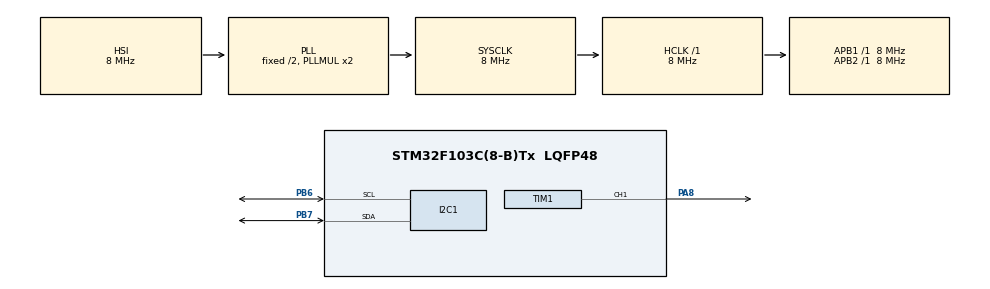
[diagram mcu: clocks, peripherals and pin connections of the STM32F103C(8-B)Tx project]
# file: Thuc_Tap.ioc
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Mcu.Family=STM32F1
Mcu.Name=STM32F103C(8-B)Tx
Mcu.Package=LQFP48
NVIC.I2C1_EV_IRQn=true\:0\:0\:false\:false\:true\:true\:true\:true
NVIC.PriorityGroup=NVIC_PRIORITYGROUP_4
PA13.Mode=Serial_Wire
PA13.Signal=SYS_JTMS-SWDIO
PA14.Mode=Serial_Wire
PA14.Signal=SYS_JTCK-SWCLK
PA8.Signal=S_TIM1_CH1
PB6.Mode=I2C
PB6.Signal=I2C1_SCL
PB7.Mode=I2C
PB7.Signal=I2C1_SDA
ProjectManager.HeapSize=0x200
ProjectManager.StackSize=0x400
ProjectManager.TargetToolchain=MDK-ARM V5.32
RCC.AHBFreq_Value=8000000
RCC.APB1Freq_Value=8000000
RCC.APB1TimFreq_Value=8000000
RCC.APB2Freq_Value=8000000
RCC.APB2TimFreq_Value=8000000
RCC.HCLKFreq_Value=8000000
RCC.SYSCLKFreq_VALUE=8000000
RCC.SYSCLKSource=RCC_SYSCLKSOURCE_PLLCLK
RCC.USBFreq_Value=8000000
SH.S_TIM1_CH1.0=TIM1_CH1,PWM Generation1 CH1
TIM1.Channel-PWM\ Generation1\ CH1=TIM_CHANNEL_1
TIM1.Period=999
TIM1.Prescaler=159
TIM1.Pulse-PWM\ Generation1\ CH1=100
VP_TIM1_VS_ClockSourceINT.Mode=Internal
board=custom

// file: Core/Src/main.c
/* USER CODE BEGIN Header */
/**
  ******************************************************************************
  * @file           : main.c
  * @brief          : Main program body
  ******************************************************************************
  * @attention
  *
  * Copyright (c) 2022 STMicroelectronics.
  * All rights reserved.
  *
  * This software is licensed under terms that can be found in the LICENSE file
  * in the root directory of this software component.
  * If no LICENSE file comes with this software, it is provided AS-IS.
  *
  ******************************************************************************
  */
/* USER CODE END Header */
#include "main.h"

/* USER CODE BEGIN Includes */
#include "DS3231.h"
#include "SG90.h"
/* USER CODE END Includes */

/* USER CODE BEGIN PTD */
DS3231_Name DS3231;
Servo_Name servo;
/* USER CODE END PTD */

/* USER CODE BEGIN PM */
struct alarm
{
	uint8_t hour;
	uint8_t min;
	uint8_t sec;
};
const struct alarm alarm1= {14,35,0};
/* USER CODE END PM */

I2C_HandleTypeDef hi2c1;

TIM_HandleTypeDef htim1;

/* USER CODE BEGIN PV */
//uint8_t val=0;
/* USER CODE END PV */

void SystemClock_Config(void);
static void MX_GPIO_Init(void);
static void MX_I2C1_Init(void);
static void MX_TIM1_Init(void);

int main(void)
{
  /* USER CODE BEGIN 1 */
	uint8_t status=1;
  /* USER CODE END 1 */

  /* MCU Configuration--------------------------------------------------------*/

  /* Reset of all peripherals, Initializes the Flash interface and the Systick. */
  HAL_Init();

  /* Configure the system clock */
  SystemClock_Config();

  /* Initialize all configured peripherals */
  MX_GPIO_Init();
  MX_I2C1_Init();
  MX_TIM1_Init();
  /* USER CODE BEGIN 2 */
	DS3231_Init(&DS3231,&hi2c1);
	DS3231_Set_Time(&DS3231,14,31,21);
	DS3231_Set_Date(&DS3231,8,11,12,22);
	Servo_Init(&servo,&htim1,TIM_CHANNEL_1,10);
	Servo_Start(&servo);
  /* USER CODE END 2 */

  /* Infinite loop */
  while (1)
  {

    /* USER CODE BEGIN 3 */
		DS3231_Get_Time(&DS3231);
		DS3231_Get_Date(&DS3231);
		/*if(DS3231.hours==alarm1.hour&&DS3231.min==alarm1.min&&status==1)
		{
			Spin_Open_servo(&servo);
		  HAL_Delay(5000);
		  Spin_Close_servo(&servo);
			status=0;
		}
		*/
		Spin_Open_servo(&servo);
		HAL_Delay(5000);
		Spin_Close_servo(&servo);
		HAL_Delay(5000);
  }
  /* USER CODE END 3 */
}

void SystemClock_Config(void)
{
  RCC_OscInitTypeDef RCC_OscInitStruct = {0};
  RCC_ClkInitTypeDef RCC_ClkInitStruct = {0};

  /** Initializes the RCC Oscillators according to the specified parameters
  * in the RCC_OscInitTypeDef structure.
  */
  RCC_OscInitStruct.OscillatorType = RCC_OSCILLATORTYPE_HSI;
  RCC_OscInitStruct.HSIState = RCC_HSI_ON;
  RCC_OscInitStruct.HSICalibrationValue = RCC_HSICALIBRATION_DEFAULT;
  RCC_OscInitStruct.PLL.PLLState = RCC_PLL_ON;
  RCC_OscInitStruct.PLL.PLLSource = RCC_PLLSOURCE_HSI_DIV2;
  RCC_OscInitStruct.PLL.PLLMUL = RCC_PLL_MUL2;
  if (HAL_RCC_OscConfig(&RCC_OscInitStruct) != HAL_OK)
  {
    Error_Handler();
  }

  /** Initializes the CPU, AHB and APB buses clocks
  */
  RCC_ClkInitStruct.ClockType = RCC_CLOCKTYPE_HCLK|RCC_CLOCKTYPE_SYSCLK
                              |RCC_CLOCKTYPE_PCLK1|RCC_CLOCKTYPE_PCLK2;
  RCC_ClkInitStruct.SYSCLKSource = RCC_SYSCLKSOURCE_PLLCLK;
  RCC_ClkInitStruct.AHBCLKDivider = RCC_SYSCLK_DIV1;
  RCC_ClkInitStruct.APB1CLKDivider = RCC_HCLK_DIV1;
  RCC_ClkInitStruct.APB2CLKDivider = RCC_HCLK_DIV1;

  if (HAL_RCC_ClockConfig(&RCC_ClkInitStruct, FLASH_LATENCY_0) != HAL_OK)
  {
    Error_Handler();
  }
}

static void MX_I2C1_Init(void)
{

  hi2c1.Instance = I2C1;
  hi2c1.Init.ClockSpeed = 100000;
  hi2c1.Init.DutyCycle = I2C_DUTYCYCLE_2;
  hi2c1.Init.OwnAddress1 = 0;
  hi2c1.Init.AddressingMode = I2C_ADDRESSINGMODE_7BIT;
  hi2c1.Init.DualAddressMode = I2C_DUALADDRESS_DISABLE;
  hi2c1.Init.OwnAddress2 = 0;
  hi2c1.Init.GeneralCallMode = I2C_GENERALCALL_DISABLE;
  hi2c1.Init.NoStretchMode = I2C_NOSTRETCH_DISABLE;
  if (HAL_I2C_Init(&hi2c1) != HAL_OK)
  {
    Error_Handler();
  }

}

static void MX_TIM1_Init(void)
{

  TIM_ClockConfigTypeDef sClockSourceConfig = {0};
  TIM_MasterConfigTypeDef sMasterConfig = {0};
  TIM_OC_InitTypeDef sConfigOC = {0};
  TIM_BreakDeadTimeConfigTypeDef sBreakDeadTimeConfig = {0};

  htim1.Instance = TIM1;
  htim1.Init.Prescaler = 159;
  htim1.Init.CounterMode = TIM_COUNTERMODE_UP;
  htim1.Init.Period = 999;
  htim1.Init.ClockDivision = TIM_CLOCKDIVISION_DIV1;
  htim1.Init.RepetitionCounter = 0;
  htim1.Init.AutoReloadPreload = TIM_AUTORELOAD_PRELOAD_DISABLE;
  if (HAL_TIM_Base_Init(&htim1) != HAL_OK)
  {
    Error_Handler();
  }
  sClockSourceConfig.ClockSource = TIM_CLOCKSOURCE_INTERNAL;
  if (HAL_TIM_ConfigClockSource(&htim1, &sClockSourceConfig) != HAL_OK)
  {
    Error_Handler();
  }
  if (HAL_TIM_PWM_Init(&htim1) != HAL_OK)
  {
    Error_Handler();
  }
  sMasterConfig.MasterOutputTrigger = TIM_TRGO_RESET;
  sMasterConfig.MasterSlaveMode = TIM_MASTERSLAVEMODE_DISABLE;
  if (HAL_TIMEx_MasterConfigSynchronization(&htim1, &sMasterConfig) != HAL_OK)
  {
    Error_Handler();
  }
  sConfigOC.OCMode = TIM_OCMODE_PWM1;
  sConfigOC.Pulse = 100;
  sConfigOC.OCPolarity = TIM_OCPOLARITY_HIGH;
  sConfigOC.OCNPolarity = TIM_OCNPOLARITY_HIGH;
  sConfigOC.OCFastMode = TIM_OCFAST_DISABLE;
  sConfigOC.OCIdleState = TIM_OCIDLESTATE_RESET;
  sConfigOC.OCNIdleState = TIM_OCNIDLESTATE_RESET;
  if (HAL_TIM_PWM_ConfigChannel(&htim1, &sConfigOC, TIM_CHANNEL_1) != HAL_OK)
  {
    Error_Handler();
  }
  sBreakDeadTimeConfig.OffStateRunMode = TIM_OSSR_DISABLE;
  sBreakDeadTimeConfig.OffStateIDLEMode = TIM_OSSI_DISABLE;
  sBreakDeadTimeConfig.LockLevel = TIM_LOCKLEVEL_OFF;
  sBreakDeadTimeConfig.DeadTime = 0;
  sBreakDeadTimeConfig.BreakState = TIM_BREAK_DISABLE;
  sBreakDeadTimeConfig.BreakPolarity = TIM_BREAKPOLARITY_HIGH;
  sBreakDeadTimeConfig.AutomaticOutput = TIM_AUTOMATICOUTPUT_DISABLE;
  if (HAL_TIMEx_ConfigBreakDeadTime(&htim1, &sBreakDeadTimeConfig) != HAL_OK)
  {
    Error_Handler();
  }
  HAL_TIM_MspPostInit(&htim1);

}

static void MX_GPIO_Init(void)
{

  /* GPIO Ports Clock Enable */
  __HAL_RCC_GPIOA_CLK_ENABLE();
  __HAL_RCC_GPIOB_CLK_ENABLE();

}

void Error_Handler(void)
{
  __disable_irq();
  while (1)
  {
  }
}
